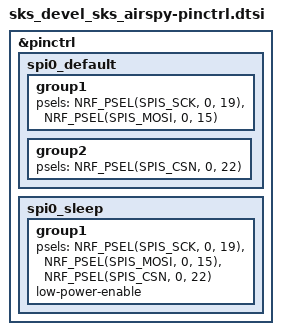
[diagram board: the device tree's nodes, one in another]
/*
 * Copyright (c) 2022 Nordic Semiconductor
 * SPDX-License-Identifier: Apache-2.0
 */

&pinctrl {
	// uart0_default: uart0_default {
	// 	group1 {
	// 		psels = <NRF_PSEL(UART_TX, 0, 5)>,
	// 			<NRF_PSEL(UART_RX, 0, 4)>,
	// 			<NRF_PSEL(UART_CTS, 0, 31)>,
	// 			<NRF_PSEL(UART_RTS, 0, 30)>;
	// 	};
	// };

	// uart0_sleep: uart0_sleep {
	// 	group1 {
	// 		psels = <NRF_PSEL(UART_TX, 0, 5)>,
	// 			<NRF_PSEL(UART_RX, 0, 4)>,
	// 			<NRF_PSEL(UART_CTS, 0, 31)>,
	// 			<NRF_PSEL(UART_RTS, 0, 30)>;
	// 		low-power-enable;
	// 	};
	// };

	spi0_default: spi0_default {
		group1 {
			psels =
				<NRF_PSEL(SPIS_SCK, 0, 19)>,
				<NRF_PSEL(SPIS_MOSI, 0, 15)>;
			// bias-pull-down;
		};
		group2 {
			psels =
				<NRF_PSEL(SPIS_CSN, 0, 22)>;
			// // init CS with pull up
			// bias-pull-up;
		};
	};	

	spi0_sleep: spi0_sleep {
		group1 {
			psels =
				<NRF_PSEL(SPIS_SCK, 0, 19)>,
				<NRF_PSEL(SPIS_MOSI, 0, 15)>,
				<NRF_PSEL(SPIS_CSN, 0, 22)>;
			low-power-enable;
		};
	};
};
